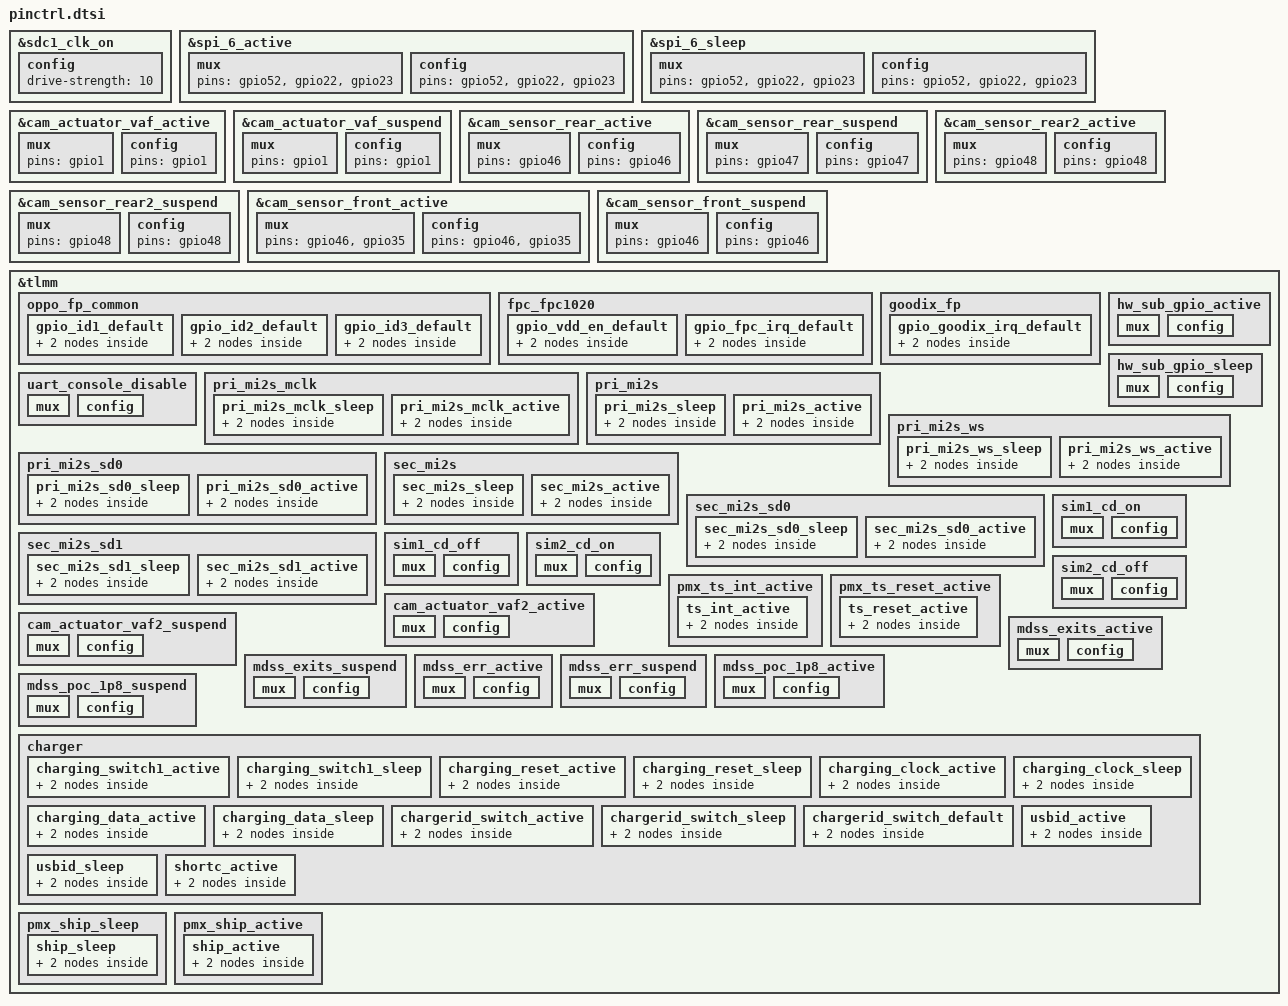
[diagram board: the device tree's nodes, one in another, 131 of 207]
/* Copyright (c) 2019, The Linux Foundation. All rights reserved.
 *
 * This program is free software; you can redistribute it and/or modify
 * it under the terms of the GNU General Public License version 2 and
 * only version 2 as published by the Free Software Foundation.
 *
 * This program is distributed in the hope that it will be useful,
 * but WITHOUT ANY WARRANTY; without even the implied warranty of
 * MERCHANTABILITY or FITNESS FOR A PARTICULAR PURPOSE.  See the
 * GNU General Public License for more details.
 */

/* diff from sdm660-pinctrl.dtsi */
&sdc1_clk_on{
    config {
        drive-strength = <10>;	/* 10 MA */
    };
};

&spi_6_active{
    mux{
        pins = "gpio52", "gpio22", "gpio23";
    };
    config{
        pins = "gpio52", "gpio22", "gpio23";
    };
};

&spi_6_sleep{
    mux{
        pins = "gpio52", "gpio22", "gpio23";
    };
    config{
        pins = "gpio52", "gpio22", "gpio23";
    };
};

&cam_actuator_vaf_active{
    mux{
        pins = "gpio1";
    };
    config{
        pins = "gpio1";
    };
};

&cam_actuator_vaf_suspend{
    mux{
        pins = "gpio1";
    };
    config{
        pins = "gpio1";
    };
};

&cam_sensor_rear_active{
    mux{
        pins = "gpio46";
    };
    config{
        pins = "gpio46";
    };
};

&cam_sensor_rear_suspend{
    mux{
        pins = "gpio47";
    };
    config{
        pins = "gpio47";
    };
};

&cam_sensor_rear2_active{
    mux{
        pins = "gpio48";
    };
    config{
        pins = "gpio48";
    };
};

&cam_sensor_rear2_suspend{
    mux{
        pins = "gpio48";
    };
    config{
        pins = "gpio48";
    };
};

&cam_sensor_front_active{
    mux{
        pins = "gpio46", "gpio35";
    };
    config{
        pins = "gpio46", "gpio35";
    };
};

&cam_sensor_front_suspend{
    mux{
        pins = "gpio46";
    };
    config{
        pins = "gpio46";
    };
};

&tlmm{
    oppo_fp_common{
        gpio_id1_default: gpio_id1_default {
            mux {
                pins = "gpio62";
                function = "gpio";
            };
            config {
                pins = "gpio62";
                drive-strength = <2>;
                bias-pull-up;
                input-enable;
            };
        };

        gpio_id2_default: gpio_id2_default {
            mux {
                pins = "gpio74";
                function = "gpio";
            };
            config {
                pins = "gpio74";
                drive-strength = <2>;
                bias-pull-up;
                input-enable;
            };
        };

        gpio_id3_default: gpio_id3_default {
            mux {
                pins = "gpio77";
                function = "gpio";
            };
            config {
                pins = "gpio77";
                drive-strength = <2>;
                bias-pull-up;
                input-enable;
            };
        };
    };

    fpc_fpc1020{
		gpio_vdd_en_default: gpio_vdd_en_default {
			mux {
				pins = "gpio40";
				function = "gpio";
			};
			config {
				pins = "gpio40";
				drive-strength = <2>;
				bias-pull-down;
				output-low;
			};
		};

        gpio_fpc_irq_default: gpio_fpc_irq_default {
			mux {
				pins = "gpio72";
				function = "gpio";
			};
			config {
				pins = "gpio72";
				drive-strength = <2>;
				bias-pull-up;
				input-enable;
			};
		};
    };

    goodix_fp{
        gpio_goodix_irq_default: gpio_goodix_irq_default {
            mux {
                pins = "gpio72";
                function = "gpio";
            };
            config {
                pins = "gpio72";
                drive-strength = <2>;
                bias-disable;
                input-enable;
            };
        };
    };

    hw_sub_gpio_active: hw_sub_gpio_active {
		/* active state */
		mux {
			pins = "gpio30", "gpio31";
			function = "gpio";
		};
		config {
			pins = "gpio30", "gpio31";
			drive-strength = <2>; /* 2 MA */
			bias-pull-up;
		};
	};

	hw_sub_gpio_sleep: hw_sub_gpio_sleep {
		/* sleep state */
		mux {
			pins = "gpio30", "gpio31";
			function = "gpio";
		};
		config {
			pins = "gpio30", "gpio31";
			drive-strength = <2>; /* 2 MA */
			bias-pull-down; /* PULL DOWN */
		};
	};

    uart_console_disable: uart_console_disable {
        mux {
            pins = "gpio4", "gpio5";
            function = "gpio";
        };

        config {
            pins = "gpio4", "gpio5";
            drive-strength = <2>;
            input-enable;
            bias-disable;
        };
    };

    pri_mi2s_mclk {
        pri_mi2s_mclk_sleep: pri_mi2s_mclk_sleep {
            mux {
                pins = "gpio61";
                function = "pri_mi2s";
            };

            config {
                pins = "gpio61";
                drive-strength = <2>;   /* 2 mA */
                bias-pull-down;         /* PULL DOWN */
                output-low;
            };
        };

        pri_mi2s_mclk_active: pri_mi2s_mclk_active {
            mux {
                pins = "gpio61";
                function = "pri_mi2s";
            };
            config {
                pins = "gpio61";
                drive-strength = <8>;   /* 8 mA */
                bias-disable;           /* NO PULL */
                output-high;
            };
        };
    };

    pri_mi2s {
        pri_mi2s_sleep: pri_mi2s_sleep {
            mux {
                pins = "gpio12";
                function = "pri_mi2s";
            };

            config {
                pins = "gpio12";
                drive-strength = <2>;   /* 2 mA */
                bias-pull-down;         /* PULL DOWN */
                output-low;
            };
        };

        pri_mi2s_active: pri_mi2s_active {
            mux {
                pins = "gpio12";
                function = "pri_mi2s";
            };
            config {
                pins = "gpio12";
                drive-strength = <8>;   /* 8 mA */
                bias-disable;           /* NO PULL */
                output-high;
            };
        };
    };

    pri_mi2s_ws {
        pri_mi2s_ws_sleep: pri_mi2s_ws_sleep {
            mux {
                pins = "gpio13";
                function = "pri_mi2s_ws";
            };

            config {
                pins = "gpio13";
                drive-strength = <2>;   /* 2 mA */
                bias-pull-down;         /* PULL DOWN */
                output-low;
            };
        };

        pri_mi2s_ws_active: pri_mi2s_ws_active {
            mux {
                pins = "gpio13";
                function = "pri_mi2s_ws";
            };
            config {
                pins = "gpio13";
                drive-strength = <8>;   /* 8 mA */
                bias-disable;           /* NO PULL */
                output-high;
            };
        };
    };

    pri_mi2s_sd0 {
        pri_mi2s_sd0_sleep: pri_mi2s_sd0_sleep {
            mux {
                pins = "gpio14";
                function = "pri_mi2s";
            };
            config {
                pins = "gpio14";
                drive-strength = <2>;   /* 2 mA */
                bias-pull-down;         /* PULL DOWN */
                output-low;
            };
        };

        pri_mi2s_sd0_active: pri_mi2s_sd0_active {
            mux {
                pins = "gpio14";
                function = "pri_mi2s";
            };
            config {
                pins = "gpio14";
                drive-strength = <8>;   /* 8 mA */
                bias-disable;           /* NO PULL */
                output-high;
            };
        };
    };

    sec_mi2s {
        sec_mi2s_sleep: sec_mi2s_sleep {
            mux {
                pins = "gpio24", "gpio25";
                function = "sec_mi2s";
            };
            config {
                pins = "gpio24", "gpio25";
                drive-strength = <2>;   /* 2 mA */
                bias-pull-down;         /* PULL DOWN */
                output-low;
            };
        };

        sec_mi2s_active: sec_mi2s_active {
            mux {
                pins = "gpio24", "gpio25";
                function = "sec_mi2s";
            };
            config {
                pins = "gpio24", "gpio25";
                drive-strength = <8>;   /* 8 mA */
                output-high;
            };
        };
    };

    sec_mi2s_sd0 {
        sec_mi2s_sd0_sleep: sec_mi2s_sd0_sleep {
            mux {
                pins = "gpio26";
                function = "sec_mi2s";
            };
            config {
                pins = "gpio26";
                drive-strength = <2>;   /* 2 mA */
                bias-pull-down;         /* PULL DOWN */
                input-enable;
            };
        };

        sec_mi2s_sd0_active: sec_mi2s_sd0_active {
            mux {
                pins = "gpio26";
                function = "sec_mi2s";
            };
            config {
                pins = "gpio26";
                drive-strength = <8>;   /* 8 mA */
                input-enable;
            };
        };
    };

    sec_mi2s_sd1 {
        sec_mi2s_sd1_sleep: sec_mi2s_sd1_sleep {
            mux {
                pins = "gpio27";
                function = "sec_mi2s";
            };
            config {
                pins = "gpio27";
                drive-strength = <2>;   /* 2 mA */
                bias-pull-down;         /* PULL DOWN */
                output-low;
            };
        };

        sec_mi2s_sd1_active: sec_mi2s_sd1_active {
            mux {
                pins = "gpio27";
                function = "sec_mi2s";
            };
            config {
                pins = "gpio27";
                drive-strength = <8>;   /* 8 mA */
                output-high;
            };
        };
    };

    sim1_cd_on: sim1_cd_on {
        mux {
            pins = "gpio90";
            function = "gpio";
        };

        config {
            pins = "gpio90";
            bias-pull-up;           /* pull up */
            drive-strength = <2>;   /* 2 MA */
        };
    };

    sim1_cd_off: sim1_cd_off {
        mux {
            pins = "gpio90";
            function = "gpio";
        };

        config {
            pins = "gpio90";
            bias-pull-up;           /* pull up */
            drive-strength = <2>;   /* 2 MA */
        };
    };
    
    sim2_cd_on: sim2_cd_on {
        mux {
            pins = "gpio86";
            function = "gpio";
        };

        config {
            pins = "gpio86";
            bias-pull-up;           /* pull up */
            drive-strength = <2>;   /* 2 MA */
        };
    };

    sim2_cd_off: sim2_cd_off {
        mux {
            pins = "gpio86";
            function = "gpio";
        };

        config {
            pins = "gpio86";
            bias-pull-up;           /* pull up */
            drive-strength = <2>;   /* 2 MA */
        };
    };

    pmx_ts_int_active {
        ts_int_active: ts_int_active {
            mux {
                pins = "gpio67";
                function = "gpio";
            };

            config {
                pins = "gpio67";
                drive-strength = <8>;
                bias-pull-up;
            };
        };
    };

    pmx_ts_reset_active {
        ts_reset_active: ts_reset_active {
            mux {
                pins = "gpio66";
                function = "gpio";
            };

            config {
                pins = "gpio66";
                drive-strength = <8>;
                bias-disable;
            };
        };
    };

    /delete-node/ i2c_4;

    cam_actuator_vaf2_active: cam_actuator_vaf2_active {
        /* ACTUATOR POWER */
        mux {
            pins = "gpio1";
            function = "gpio";
        };

        config {
            pins = "gpio1";
            bias-disable; /* No PULL */
            drive-strength = <2>; /* 2 MA */
        };
    };

    cam_actuator_vaf2_suspend: cam_actuator_vaf2_suspend {
        /* ACTUATOR POWER */
        mux {
            pins = "gpio1";
            function = "gpio";
        };

        config {
            pins = "gpio1";
            bias-pull-down; /* PULL DOWN */
            drive-strength = <2>; /* 2 MA */
        };
    };

    /delete-node/ tlmm_gpio_key;

    mdss_exits_active: mdss_exits_active {
        mux {
            pins = "gpio73";
            function = "gpio";
        };
        config {
            pins = "gpio73";
            drive-strength = <2>; /* 2 mA */
            bias-disable = <0>; /* no pull */
            input-enable;
        };
    };

    mdss_exits_suspend: mdss_exits_suspend {
        mux {
            pins = "gpio73";
            function = "gpio";
        };
        config {
            pins = "gpio73";
            drive-strength = <2>; /* 2 mA */
            bias-pull-down; /* pull down */
            input-enable;
        };
    };

    mdss_err_active: mdss_err_active {
        mux {
            pins = "gpio56";
            function = "gpio";
        };
        config {
            pins = "gpio56";
            drive-strength = <2>; /* 2 mA */
            bias-pull-down; /* pull down*/
            input-enable;
        };
    };

    mdss_err_suspend: mdss_err_suspend {
        mux {
            pins = "gpio56";
            function = "gpio";
        };
        config {
            pins = "gpio56";
            drive-strength = <2>; /* 2 mA */
            bias-pull-down; /* pull down */
            input-enable;
        };
    };

    mdss_poc_1p8_active: mdss_poc_1p8_active {
        mux {
            pins = "gpio63";
            function = "gpio";
        };
        config {
            pins = "gpio63";
            drive-strength = <2>;
            bias-pull-up;
            output-high;
        };
    };

    mdss_poc_1p8_suspend: mdss_poc_1p8_suspend {
        mux {
            pins = "gpio63";
            function = "gpio";
        };
        config {
            pins = "gpio63";
            drive-strength = <2>;
            bias-disable;
            output-low;
        };
    };

    charger: charger {
        charging_switch1_active: charging_switch1_active {
            mux {
                pins = "gpio75";
                function = "gpio";
            };

            config {
                pins = "gpio75";
                drive-strength = <2>;
                bias-pull-up;
            };
        };

        charging_switch1_sleep: charging_switch1_sleep {
            mux {
                pins = "gpio75";
                function = "gpio";
            };

            config {
                pins = "gpio75";
                drive-strength = <2>;
                bias-pull-down;
            };
        };

        charging_reset_active: charging_reset_active {
            mux {
                pins = "gpio55";
                function = "gpio";
            };

            config {
                pins = "gpio55";
                drive-strength = <2>;
                bias-pull-up;
            };
        };

        charging_reset_sleep: charging_reset_sleep {
            mux {
                pins = "gpio55";
                function = "gpio";
            };

            config {
                pins = "gpio55";
                drive-strength = <2>;
                bias-pull-down;
            };
        };

        charging_clock_active: charging_clock_active {
            mux {
                pins = "gpio51";
                function = "gpio";
            };

            config {
                pins = "gpio51";
                drive-strength = <2>;
                bias-pull-up;
            };
        };

        charging_clock_sleep: charging_clock_sleep {
            mux {
                pins = "gpio51";
                function = "gpio";
            };

            config {
                pins = "gpio51";
                drive-strength = <2>;
                bias-pull-down;
            };
        };

        charging_data_active: charging_data_active {
            mux {
                pins = "gpio44";
                function = "gpio";
            };

            config {
                pins = "gpio44";
                drive-strength = <2>;
                bias-pull-up;
            };
        };

        charging_data_sleep: charging_data_sleep {
            mux {
                pins = "gpio44";
                function = "gpio";
            };

            config {
                pins = "gpio44";
                drive-strength = <2>;
                bias-pull-down;
            };
        };

        chargerid_switch_active: chargerid_switch_active {
            mux {
                pins = "gpio65";
                function = "gpio";
            };

            config {
                pins = "gpio65";
                drive-strength = <2>;
                bias-pull-up;
            };
        };

        chargerid_switch_sleep: chargerid_switch_sleep {
            mux {
                pins = "gpio65";
                function = "gpio";
            };

            config {
                pins = "gpio65";
                drive-strength = <2>;
                bias-pull-down;
            };
        };

        chargerid_switch_default: chargerid_switch_default {
            mux {
                pins = "gpio65";
                function = "gpio";
            };

            config {
                pins = "gpio65";
                drive-strength = <2>;
                bias-disable; /* NO PULL */
            };
        };

        usbid_active: usbid_active {
            mux {
                pins = "gpio49";
                function = "gpio";
            };

            config {
                pins = "gpio49";
                drive-strength = <2>;
                input-enable;
                bias-pull-up; /*PULL UP*/
            };
        };

        usbid_sleep: usbid_sleep {
            mux {
                pins = "gpio49";
                function = "gpio";
            };

            config {
                pins = "gpio49";
                drive-strength = <2>;
                output-low;
                bias-pull-down; /*PULL DOWN*/
            };
        };
        
        shortc_active: shortc_active {
            mux {
                pins = "gpio60";
                function = "gpio";
            };

            config {
                pins = "gpio60";
                drive-strength = <2>;
                input-enable;
                bias-pull-up; /*PULL UP*/
            };
        };
    };

    pmx_ship_sleep {
        ship_sleep: ship_sleep {
            mux {
                pins = "gpio98";
                function = "gpio";
            };

            config {
                pins = "gpio98";
                drive-strength = <2>;
                bias-pull-down;
            };
        };
    };

    pmx_ship_active {
        ship_active: ship_active {
            mux {
                pins = "gpio98";
                function = "gpio";
            };

            config {
                pins = "gpio98";
                drive-strength = <2>;
                bias-pull-up;
            };
        };
    };
};

&tlmm {
    /delete-node/ trigout_a;
};
